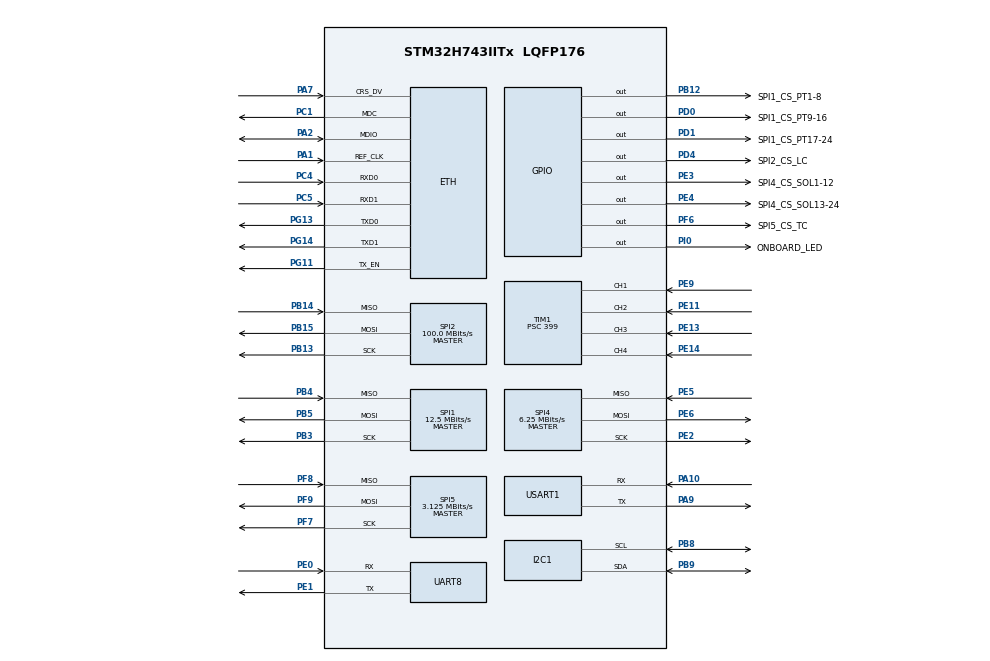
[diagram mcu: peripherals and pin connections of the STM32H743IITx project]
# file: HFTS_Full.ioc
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CORTEX_M7.default_mode_Activation=1
ETH.MediaInterface=HAL_ETH_RMII_MODE
FREERTOS.Tasks01=defaultTask,0,128,StartDefaultTask,Default,NULL,Dynamic,NULL,NULL
I2C1.Timing=0x10C0ECFF
Mcu.Family=STM32H7
Mcu.Name=STM32H743IITx
Mcu.Package=LQFP176
Mcu.UserConstants=I2C1_BUS_HZ,100000;TMP117_ADDRESS,0b1001000x
NVIC.PriorityGroup=NVIC_PRIORITYGROUP_4
NVIC.TIM1_CC_IRQn=true\:5\:0\:false\:false\:true\:true\:true\:true\:true
PA1.Mode=RMII
PA1.Signal=ETH_REF_CLK
PA10.Mode=Asynchronous
PA10.Signal=USART1_RX
PA13\ (JTMS/SWDIO).Mode=Serial_Wire
PA13\ (JTMS/SWDIO).Signal=DEBUG_JTMS-SWDIO
PA14\ (JTCK/SWCLK).Mode=Serial_Wire
PA14\ (JTCK/SWCLK).Signal=DEBUG_JTCK-SWCLK
PA2.Mode=RMII
PA2.Signal=ETH_MDIO
PA7.Mode=RMII
PA7.Signal=ETH_CRS_DV
PA9.Mode=Asynchronous
PA9.Signal=USART1_TX
PB12.GPIO_Label=SPI1_CS_PT1-8
PB12.PinState=GPIO_PIN_SET
PB12.Signal=GPIO_Output
PB13.Mode=Full_Duplex_Master
PB13.Signal=SPI2_SCK
PB14.Mode=Full_Duplex_Master
PB14.Signal=SPI2_MISO
PB15.Mode=Full_Duplex_Master
PB15.Signal=SPI2_MOSI
PB3\ (JTDO/TRACESWO).Mode=Full_Duplex_Master
PB3\ (JTDO/TRACESWO).Signal=SPI1_SCK
PB4\ (NJTRST).Mode=Full_Duplex_Master
PB4\ (NJTRST).Signal=SPI1_MISO
PB5.Mode=Full_Duplex_Master
PB5.Signal=SPI1_MOSI
PB8.Mode=I2C
PB8.Signal=I2C1_SCL
PB9.Mode=I2C
PB9.Signal=I2C1_SDA
PC1.Mode=RMII
PC1.Signal=ETH_MDC
PC4.Mode=RMII
PC4.Signal=ETH_RXD0
PC5.Mode=RMII
PC5.Signal=ETH_RXD1
PD0.GPIO_Label=SPI1_CS_PT9-16
PD0.PinState=GPIO_PIN_SET
PD0.Signal=GPIO_Output
PD1.GPIO_Label=SPI1_CS_PT17-24
PD1.PinState=GPIO_PIN_SET
PD1.Signal=GPIO_Output
PD4.GPIO_Label=SPI2_CS_LC
PD4.PinState=GPIO_PIN_SET
PD4.Signal=GPIO_Output
PE0.Mode=Asynchronous
PE0.Signal=UART8_RX
PE1.Mode=Asynchronous
PE1.Signal=UART8_TX
PE11.Signal=S_TIM1_CH2
PE13.Signal=S_TIM1_CH3
PE14.Signal=S_TIM1_CH4
PE2.Mode=Full_Duplex_Master
PE2.Signal=SPI4_SCK
PE3.GPIO_Label=SPI4_CS_SOL1-12
PE3.PinState=GPIO_PIN_SET
PE3.Signal=GPIO_Output
PE4.GPIO_Label=SPI4_CS_SOL13-24
PE4.PinState=GPIO_PIN_SET
PE4.Signal=GPIO_Output
PE5.Mode=Full_Duplex_Master
PE5.Signal=SPI4_MISO
PE6.Mode=Full_Duplex_Master
PE6.Signal=SPI4_MOSI
PE9.Signal=S_TIM1_CH1
PF6.GPIO_Label=SPI5_CS_TC
PF6.PinState=GPIO_PIN_SET
PF6.Signal=GPIO_Output
PF7.Mode=Full_Duplex_Master
PF7.Signal=SPI5_SCK
PF8.Mode=Full_Duplex_Master
PF8.Signal=SPI5_MISO
PF9.Mode=Full_Duplex_Master
PF9.Signal=SPI5_MOSI
PG11.Mode=RMII
PG11.Signal=ETH_TX_EN
PG13.Mode=RMII
PG13.Signal=ETH_TXD0
PG14.Mode=RMII
PG14.Signal=ETH_TXD1
PH0-OSC_IN\ (PH0).Mode=HSE-External-Oscillator
PH0-OSC_IN\ (PH0).Signal=RCC_OSC_IN
PH1-OSC_OUT\ (PH1).Mode=HSE-External-Oscillator
PH1-OSC_OUT\ (PH1).Signal=RCC_OSC_OUT
PI0.GPIO_Label=ONBOARD_LED
PI0.Signal=GPIO_Output
ProjectManager.HeapSize=0x200
ProjectManager.StackSize=0x400
ProjectManager.TargetToolchain=STM32CubeIDE
RCC.ADCFreq_Value=50000000
RCC.APB1Freq_Value=100000000
RCC.APB2Freq_Value=100000000
RCC.APB3Freq_Value=100000000
RCC.APB4Freq_Value=100000000
RCC.CortexFreq_Value=400000000
RCC.D1PPRE=RCC_APB3_DIV2
RCC.D2PPRE1=RCC_APB1_DIV2
RCC.D2PPRE2=RCC_APB2_DIV2
RCC.D3PPRE=RCC_APB4_DIV2
RCC.DIVM1=2
RCC.DIVM2=2
RCC.DIVN1=64
RCC.DIVN2=16
RCC.DIVP2=4
RCC.DIVQ1=4
RCC.DIVQ2=4
RCC.HCLKFreq_Value=200000000
RCC.HPRE=RCC_HCLK_DIV2
RCC.PLL2FRACN=0
RCC.PLL3FRACN=0
RCC.PLLFRACN=0
RCC.PLLSourceVirtual=RCC_PLLSOURCE_HSE
RCC.SYSCLKFreq_VALUE=400000000
RCC.SYSCLKSource=RCC_SYSCLKSOURCE_PLLCLK
RCC.Spi45ClockSelection=RCC_SPI45CLKSOURCE_PLL2
RCC.USBFreq_Value=200000000
SH.S_TIM1_CH1.0=TIM1_CH1,Input_Capture1_from_TI1
SH.S_TIM1_CH2.0=TIM1_CH2,Input_Capture2_from_TI2
SH.S_TIM1_CH3.0=TIM1_CH3,Input_Capture3_from_TI3
SH.S_TIM1_CH4.0=TIM1_CH4,Input_Capture4_from_TI4
SPI1.BaudRatePrescaler=SPI_BAUDRATEPRESCALER_16
SPI1.CalculateBaudRate=12.5 MBits/s
SPI1.Direction=SPI_DIRECTION_2LINES
SPI1.Mode=SPI_MODE_MASTER
SPI1.VirtualType=VM_MASTER
SPI2.CalculateBaudRate=100.0 MBits/s
SPI2.Direction=SPI_DIRECTION_2LINES
SPI2.Mode=SPI_MODE_MASTER
SPI2.VirtualType=VM_MASTER
SPI4.BaudRatePrescaler=SPI_BAUDRATEPRESCALER_8
SPI4.CalculateBaudRate=6.25 MBits/s
SPI4.Direction=SPI_DIRECTION_2LINES
SPI4.Mode=SPI_MODE_MASTER
SPI4.VirtualType=VM_MASTER
SPI5.BaudRatePrescaler=SPI_BAUDRATEPRESCALER_16
SPI5.CalculateBaudRate=3.125 MBits/s
SPI5.Direction=SPI_DIRECTION_2LINES
SPI5.Mode=SPI_MODE_MASTER
SPI5.VirtualType=VM_MASTER
TIM1.Channel-Input_Capture1_from_TI1=TIM_CHANNEL_1
TIM1.Channel-Input_Capture2_from_TI2=TIM_CHANNEL_2
TIM1.Channel-Input_Capture3_from_TI3=TIM_CHANNEL_3
TIM1.Channel-Input_Capture4_from_TI4=TIM_CHANNEL_4
TIM1.ICFilter_CH1=2
TIM1.Prescaler=399
USART1.VirtualMode-Asynchronous=VM_ASYNC
VP_FREERTOS_VS_CMSIS_V1.Mode=CMSIS_V1
VP_MEMORYMAP_VS_MEMORYMAP.Mode=CurAppReg
VP_TIM1_VS_ClockSourceINT.Mode=Internal
board=custom

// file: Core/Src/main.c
/* USER CODE BEGIN Header */
/**
  ******************************************************************************
  * @file           : main.c
  * @brief          : Main program body
  ******************************************************************************
  * @attention
  *
  * Copyright (c) 2026 STMicroelectronics.
  * All rights reserved.
  *
  * This software is licensed under terms that can be found in the LICENSE file
  * in the root directory of this software component.
  * If no LICENSE file comes with this software, it is provided AS-IS.
  *
  ******************************************************************************
  */
/* USER CODE END Header */
#include "main.h"
#include "string.h"
#include "cmsis_os.h"

#if defined ( __ICCARM__ ) /*!< IAR Compiler */
#pragma location=0x30000000
ETH_DMADescTypeDef  DMARxDscrTab[ETH_RX_DESC_CNT]; /* Ethernet Rx DMA Descriptors */
#pragma location=0x30000080
ETH_DMADescTypeDef  DMATxDscrTab[ETH_TX_DESC_CNT]; /* Ethernet Tx DMA Descriptors */

#elif defined ( __CC_ARM )  /* MDK ARM Compiler */

__attribute__((at(0x30000000))) ETH_DMADescTypeDef  DMARxDscrTab[ETH_RX_DESC_CNT]; /* Ethernet Rx DMA Descriptors */
__attribute__((at(0x30000080))) ETH_DMADescTypeDef  DMATxDscrTab[ETH_TX_DESC_CNT]; /* Ethernet Tx DMA Descriptors */

#elif defined ( __GNUC__ ) /* GNU Compiler */

ETH_DMADescTypeDef DMARxDscrTab[ETH_RX_DESC_CNT] __attribute__((section(".RxDescripSection"))); /* Ethernet Rx DMA Descriptors */
ETH_DMADescTypeDef DMATxDscrTab[ETH_TX_DESC_CNT] __attribute__((section(".TxDescripSection")));   /* Ethernet Tx DMA Descriptors */
#endif

ETH_TxPacketConfig TxConfig;

ETH_HandleTypeDef heth;

I2C_HandleTypeDef hi2c1;

SPI_HandleTypeDef hspi1;
SPI_HandleTypeDef hspi2;
SPI_HandleTypeDef hspi4;
SPI_HandleTypeDef hspi5;

TIM_HandleTypeDef htim1;

UART_HandleTypeDef huart8;
UART_HandleTypeDef huart1;

osThreadId defaultTaskHandle;

void SystemClock_Config(void);
void PeriphCommonClock_Config(void);
static void MPU_Config(void);
static void MX_GPIO_Init(void);
static void MX_ETH_Init(void);
static void MX_TIM1_Init(void);
static void MX_I2C1_Init(void);
static void MX_SPI1_Init(void);
static void MX_SPI2_Init(void);
static void MX_SPI4_Init(void);
static void MX_SPI5_Init(void);
static void MX_UART8_Init(void);
static void MX_USART1_UART_Init(void);
void StartDefaultTask(void const * argument);

int main(void)
{

  /* MPU Configuration--------------------------------------------------------*/
  MPU_Config();

  /* MCU Configuration--------------------------------------------------------*/

  /* Reset of all peripherals, Initializes the Flash interface and the Systick. */
  HAL_Init();

  /* Configure the system clock */
  SystemClock_Config();

  /* Configure the peripherals common clocks */
  PeriphCommonClock_Config();

  /* Initialize all configured peripherals */
  MX_GPIO_Init();

  MX_ETH_Init();
  MX_TIM1_Init();
  MX_I2C1_Init();
  MX_SPI1_Init();
  MX_SPI2_Init();
  MX_SPI4_Init();
  MX_SPI5_Init();
  MX_UART8_Init();
  MX_USART1_UART_Init();

  /* Create the thread(s) */
  /* definition and creation of defaultTask */
  osThreadDef(defaultTask, StartDefaultTask, osPriorityNormal, 0, 128);
  defaultTaskHandle = osThreadCreate(osThread(defaultTask), NULL);

  /* Start scheduler */
  osKernelStart();

  /* We should never get here as control is now taken by the scheduler */

  /* Infinite loop */
  while (1)
  {

  }
}

void SystemClock_Config(void)
{
  RCC_OscInitTypeDef RCC_OscInitStruct = {0};
  RCC_ClkInitTypeDef RCC_ClkInitStruct = {0};

  /** Supply configuration update enable
  */
  HAL_PWREx_ConfigSupply(PWR_LDO_SUPPLY);

  /** Configure the main internal regulator output voltage
  */
  __HAL_PWR_VOLTAGESCALING_CONFIG(PWR_REGULATOR_VOLTAGE_SCALE1);

  while(!__HAL_PWR_GET_FLAG(PWR_FLAG_VOSRDY)) {}

  /** Initializes the RCC Oscillators according to the specified parameters
  * in the RCC_OscInitTypeDef structure.
  */
  RCC_OscInitStruct.OscillatorType = RCC_OSCILLATORTYPE_HSE;
  RCC_OscInitStruct.HSEState = RCC_HSE_ON;
  RCC_OscInitStruct.PLL.PLLState = RCC_PLL_ON;
  RCC_OscInitStruct.PLL.PLLSource = RCC_PLLSOURCE_HSE;
  RCC_OscInitStruct.PLL.PLLM = 2;
  RCC_OscInitStruct.PLL.PLLN = 64;
  RCC_OscInitStruct.PLL.PLLP = 2;
  RCC_OscInitStruct.PLL.PLLQ = 4;
  RCC_OscInitStruct.PLL.PLLR = 2;
  RCC_OscInitStruct.PLL.PLLRGE = RCC_PLL1VCIRANGE_3;
  RCC_OscInitStruct.PLL.PLLVCOSEL = RCC_PLL1VCOWIDE;
  RCC_OscInitStruct.PLL.PLLFRACN = 0;
  if (HAL_RCC_OscConfig(&RCC_OscInitStruct) != HAL_OK)
  {
    Error_Handler();
  }

  /** Initializes the CPU, AHB and APB buses clocks
  */
  RCC_ClkInitStruct.ClockType = RCC_CLOCKTYPE_HCLK|RCC_CLOCKTYPE_SYSCLK
                              |RCC_CLOCKTYPE_PCLK1|RCC_CLOCKTYPE_PCLK2
                              |RCC_CLOCKTYPE_D3PCLK1|RCC_CLOCKTYPE_D1PCLK1;
  RCC_ClkInitStruct.SYSCLKSource = RCC_SYSCLKSOURCE_PLLCLK;
  RCC_ClkInitStruct.SYSCLKDivider = RCC_SYSCLK_DIV1;
  RCC_ClkInitStruct.AHBCLKDivider = RCC_HCLK_DIV2;
  RCC_ClkInitStruct.APB3CLKDivider = RCC_APB3_DIV2;
  RCC_ClkInitStruct.APB1CLKDivider = RCC_APB1_DIV2;
  RCC_ClkInitStruct.APB2CLKDivider = RCC_APB2_DIV2;
  RCC_ClkInitStruct.APB4CLKDivider = RCC_APB4_DIV2;

  if (HAL_RCC_ClockConfig(&RCC_ClkInitStruct, FLASH_LATENCY_2) != HAL_OK)
  {
    Error_Handler();
  }
}

void PeriphCommonClock_Config(void)
{
  RCC_PeriphCLKInitTypeDef PeriphClkInitStruct = {0};

  /** Initializes the peripherals clock
  */
  PeriphClkInitStruct.PeriphClockSelection = RCC_PERIPHCLK_SPI4|RCC_PERIPHCLK_SPI5;
  PeriphClkInitStruct.PLL2.PLL2M = 2;
  PeriphClkInitStruct.PLL2.PLL2N = 16;
  PeriphClkInitStruct.PLL2.PLL2P = 4;
  PeriphClkInitStruct.PLL2.PLL2Q = 4;
  PeriphClkInitStruct.PLL2.PLL2R = 2;
  PeriphClkInitStruct.PLL2.PLL2RGE = RCC_PLL2VCIRANGE_3;
  PeriphClkInitStruct.PLL2.PLL2VCOSEL = RCC_PLL2VCOWIDE;
  PeriphClkInitStruct.PLL2.PLL2FRACN = 0;
  PeriphClkInitStruct.Spi45ClockSelection = RCC_SPI45CLKSOURCE_PLL2;
  if (HAL_RCCEx_PeriphCLKConfig(&PeriphClkInitStruct) != HAL_OK)
  {
    Error_Handler();
  }
}

static void MX_ETH_Init(void)
{

   static uint8_t MACAddr[6];

  heth.Instance = ETH;
  MACAddr[0] = 0x00;
  MACAddr[1] = 0x80;
  MACAddr[2] = 0xE1;
  MACAddr[3] = 0x00;
  MACAddr[4] = 0x00;
  MACAddr[5] = 0x00;
  heth.Init.MACAddr = &MACAddr[0];
  heth.Init.MediaInterface = HAL_ETH_RMII_MODE;
  heth.Init.TxDesc = DMATxDscrTab;
  heth.Init.RxDesc = DMARxDscrTab;
  heth.Init.RxBuffLen = 1536;

  if (HAL_ETH_Init(&heth) != HAL_OK)
  {
    Error_Handler();
  }

  memset(&TxConfig, 0 , sizeof(ETH_TxPacketConfig));
  TxConfig.Attributes = ETH_TX_PACKETS_FEATURES_CSUM | ETH_TX_PACKETS_FEATURES_CRCPAD;
  TxConfig.ChecksumCtrl = ETH_CHECKSUM_IPHDR_PAYLOAD_INSERT_PHDR_CALC;
  TxConfig.CRCPadCtrl = ETH_CRC_PAD_INSERT;

}

static void MX_I2C1_Init(void)
{

  hi2c1.Instance = I2C1;
  hi2c1.Init.Timing = 0x10C0ECFF;
  hi2c1.Init.OwnAddress1 = 0;
  hi2c1.Init.AddressingMode = I2C_ADDRESSINGMODE_7BIT;
  hi2c1.Init.DualAddressMode = I2C_DUALADDRESS_DISABLE;
  hi2c1.Init.OwnAddress2 = 0;
  hi2c1.Init.OwnAddress2Masks = I2C_OA2_NOMASK;
  hi2c1.Init.GeneralCallMode = I2C_GENERALCALL_DISABLE;
  hi2c1.Init.NoStretchMode = I2C_NOSTRETCH_DISABLE;
  if (HAL_I2C_Init(&hi2c1) != HAL_OK)
  {
    Error_Handler();
  }

  /** Configure Analogue filter
  */
  if (HAL_I2CEx_ConfigAnalogFilter(&hi2c1, I2C_ANALOGFILTER_ENABLE) != HAL_OK)
  {
    Error_Handler();
  }

  /** Configure Digital filter
  */
  if (HAL_I2CEx_ConfigDigitalFilter(&hi2c1, 0) != HAL_OK)
  {
    Error_Handler();
  }

}

static void MX_SPI1_Init(void)
{

  /* SPI1 parameter configuration*/
  hspi1.Instance = SPI1;
  hspi1.Init.Mode = SPI_MODE_MASTER;
  hspi1.Init.Direction = SPI_DIRECTION_2LINES;
  hspi1.Init.DataSize = SPI_DATASIZE_4BIT;
  hspi1.Init.CLKPolarity = SPI_POLARITY_LOW;
  hspi1.Init.CLKPhase = SPI_PHASE_1EDGE;
  hspi1.Init.NSS = SPI_NSS_SOFT;
  hspi1.Init.BaudRatePrescaler = SPI_BAUDRATEPRESCALER_16;
  hspi1.Init.FirstBit = SPI_FIRSTBIT_MSB;
  hspi1.Init.TIMode = SPI_TIMODE_DISABLE;
  hspi1.Init.CRCCalculation = SPI_CRCCALCULATION_DISABLE;
  hspi1.Init.CRCPolynomial = 0x0;
  hspi1.Init.NSSPMode = SPI_NSS_PULSE_ENABLE;
  hspi1.Init.NSSPolarity = SPI_NSS_POLARITY_LOW;
  hspi1.Init.FifoThreshold = SPI_FIFO_THRESHOLD_01DATA;
  hspi1.Init.TxCRCInitializationPattern = SPI_CRC_INITIALIZATION_ALL_ZERO_PATTERN;
  hspi1.Init.RxCRCInitializationPattern = SPI_CRC_INITIALIZATION_ALL_ZERO_PATTERN;
  hspi1.Init.MasterSSIdleness = SPI_MASTER_SS_IDLENESS_00CYCLE;
  hspi1.Init.MasterInterDataIdleness = SPI_MASTER_INTERDATA_IDLENESS_00CYCLE;
  hspi1.Init.MasterReceiverAutoSusp = SPI_MASTER_RX_AUTOSUSP_DISABLE;
  hspi1.Init.MasterKeepIOState = SPI_MASTER_KEEP_IO_STATE_DISABLE;
  hspi1.Init.IOSwap = SPI_IO_SWAP_DISABLE;
  if (HAL_SPI_Init(&hspi1) != HAL_OK)
  {
    Error_Handler();
  }

}

static void MX_SPI2_Init(void)
{

  /* SPI2 parameter configuration*/
  hspi2.Instance = SPI2;
  hspi2.Init.Mode = SPI_MODE_MASTER;
  hspi2.Init.Direction = SPI_DIRECTION_2LINES;
  hspi2.Init.DataSize = SPI_DATASIZE_4BIT;
  hspi2.Init.CLKPolarity = SPI_POLARITY_LOW;
  hspi2.Init.CLKPhase = SPI_PHASE_1EDGE;
  hspi2.Init.NSS = SPI_NSS_SOFT;
  hspi2.Init.BaudRatePrescaler = SPI_BAUDRATEPRESCALER_2;
  hspi2.Init.FirstBit = SPI_FIRSTBIT_MSB;
  hspi2.Init.TIMode = SPI_TIMODE_DISABLE;
  hspi2.Init.CRCCalculation = SPI_CRCCALCULATION_DISABLE;
  hspi2.Init.CRCPolynomial = 0x0;
  hspi2.Init.NSSPMode = SPI_NSS_PULSE_ENABLE;
  hspi2.Init.NSSPolarity = SPI_NSS_POLARITY_LOW;
  hspi2.Init.FifoThreshold = SPI_FIFO_THRESHOLD_01DATA;
  hspi2.Init.TxCRCInitializationPattern = SPI_CRC_INITIALIZATION_ALL_ZERO_PATTERN;
  hspi2.Init.RxCRCInitializationPattern = SPI_CRC_INITIALIZATION_ALL_ZERO_PATTERN;
  hspi2.Init.MasterSSIdleness = SPI_MASTER_SS_IDLENESS_00CYCLE;
  hspi2.Init.MasterInterDataIdleness = SPI_MASTER_INTERDATA_IDLENESS_00CYCLE;
  hspi2.Init.MasterReceiverAutoSusp = SPI_MASTER_RX_AUTOSUSP_DISABLE;
  hspi2.Init.MasterKeepIOState = SPI_MASTER_KEEP_IO_STATE_DISABLE;
  hspi2.Init.IOSwap = SPI_IO_SWAP_DISABLE;
  if (HAL_SPI_Init(&hspi2) != HAL_OK)
  {
    Error_Handler();
  }

}

static void MX_SPI4_Init(void)
{

  /* SPI4 parameter configuration*/
  hspi4.Instance = SPI4;
  hspi4.Init.Mode = SPI_MODE_MASTER;
  hspi4.Init.Direction = SPI_DIRECTION_2LINES;
  hspi4.Init.DataSize = SPI_DATASIZE_4BIT;
  hspi4.Init.CLKPolarity = SPI_POLARITY_LOW;
  hspi4.Init.CLKPhase = SPI_PHASE_1EDGE;
  hspi4.Init.NSS = SPI_NSS_SOFT;
  hspi4.Init.BaudRatePrescaler = SPI_BAUDRATEPRESCALER_8;
  hspi4.Init.FirstBit = SPI_FIRSTBIT_MSB;
  hspi4.Init.TIMode = SPI_TIMODE_DISABLE;
  hspi4.Init.CRCCalculation = SPI_CRCCALCULATION_DISABLE;
  hspi4.Init.CRCPolynomial = 0x0;
  hspi4.Init.NSSPMode = SPI_NSS_PULSE_ENABLE;
  hspi4.Init.NSSPolarity = SPI_NSS_POLARITY_LOW;
  hspi4.Init.FifoThreshold = SPI_FIFO_THRESHOLD_01DATA;
  hspi4.Init.TxCRCInitializationPattern = SPI_CRC_INITIALIZATION_ALL_ZERO_PATTERN;
  hspi4.Init.RxCRCInitializationPattern = SPI_CRC_INITIALIZATION_ALL_ZERO_PATTERN;
  hspi4.Init.MasterSSIdleness = SPI_MASTER_SS_IDLENESS_00CYCLE;
  hspi4.Init.MasterInterDataIdleness = SPI_MASTER_INTERDATA_IDLENESS_00CYCLE;
  hspi4.Init.MasterReceiverAutoSusp = SPI_MASTER_RX_AUTOSUSP_DISABLE;
  hspi4.Init.MasterKeepIOState = SPI_MASTER_KEEP_IO_STATE_DISABLE;
  hspi4.Init.IOSwap = SPI_IO_SWAP_DISABLE;
  if (HAL_SPI_Init(&hspi4) != HAL_OK)
  {
    Error_Handler();
  }

}

static void MX_SPI5_Init(void)
{

  /* SPI5 parameter configuration*/
  hspi5.Instance = SPI5;
  hspi5.Init.Mode = SPI_MODE_MASTER;
  hspi5.Init.Direction = SPI_DIRECTION_2LINES;
  hspi5.Init.DataSize = SPI_DATASIZE_4BIT;
  hspi5.Init.CLKPolarity = SPI_POLARITY_LOW;
  hspi5.Init.CLKPhase = SPI_PHASE_1EDGE;
  hspi5.Init.NSS = SPI_NSS_SOFT;
  hspi5.Init.BaudRatePrescaler = SPI_BAUDRATEPRESCALER_16;
  hspi5.Init.FirstBit = SPI_FIRSTBIT_MSB;
  hspi5.Init.TIMode = SPI_TIMODE_DISABLE;
  hspi5.Init.CRCCalculation = SPI_CRCCALCULATION_DISABLE;
  hspi5.Init.CRCPolynomial = 0x0;
  hspi5.Init.NSSPMode = SPI_NSS_PULSE_ENABLE;
  hspi5.Init.NSSPolarity = SPI_NSS_POLARITY_LOW;
  hspi5.Init.FifoThreshold = SPI_FIFO_THRESHOLD_01DATA;
  hspi5.Init.TxCRCInitializationPattern = SPI_CRC_INITIALIZATION_ALL_ZERO_PATTERN;
  hspi5.Init.RxCRCInitializationPattern = SPI_CRC_INITIALIZATION_ALL_ZERO_PATTERN;
  hspi5.Init.MasterSSIdleness = SPI_MASTER_SS_IDLENESS_00CYCLE;
  hspi5.Init.MasterInterDataIdleness = SPI_MASTER_INTERDATA_IDLENESS_00CYCLE;
  hspi5.Init.MasterReceiverAutoSusp = SPI_MASTER_RX_AUTOSUSP_DISABLE;
  hspi5.Init.MasterKeepIOState = SPI_MASTER_KEEP_IO_STATE_DISABLE;
  hspi5.Init.IOSwap = SPI_IO_SWAP_DISABLE;
  if (HAL_SPI_Init(&hspi5) != HAL_OK)
  {
    Error_Handler();
  }

}

static void MX_TIM1_Init(void)
{

  TIM_ClockConfigTypeDef sClockSourceConfig = {0};
  TIM_MasterConfigTypeDef sMasterConfig = {0};
  TIM_IC_InitTypeDef sConfigIC = {0};

  htim1.Instance = TIM1;
  htim1.Init.Prescaler = 399;
  htim1.Init.CounterMode = TIM_COUNTERMODE_UP;
  htim1.Init.Period = 65535;
  htim1.Init.ClockDivision = TIM_CLOCKDIVISION_DIV1;
  htim1.Init.RepetitionCounter = 0;
  htim1.Init.AutoReloadPreload = TIM_AUTORELOAD_PRELOAD_DISABLE;
  if (HAL_TIM_Base_Init(&htim1) != HAL_OK)
  {
    Error_Handler();
  }
  sClockSourceConfig.ClockSource = TIM_CLOCKSOURCE_INTERNAL;
  if (HAL_TIM_ConfigClockSource(&htim1, &sClockSourceConfig) != HAL_OK)
  {
    Error_Handler();
  }
  if (HAL_TIM_IC_Init(&htim1) != HAL_OK)
  {
    Error_Handler();
  }
  sMasterConfig.MasterOutputTrigger = TIM_TRGO_RESET;
  sMasterConfig.MasterOutputTrigger2 = TIM_TRGO2_RESET;
  sMasterConfig.MasterSlaveMode = TIM_MASTERSLAVEMODE_DISABLE;
  if (HAL_TIMEx_MasterConfigSynchronization(&htim1, &sMasterConfig) != HAL_OK)
  {
    Error_Handler();
  }
  sConfigIC.ICPolarity = TIM_INPUTCHANNELPOLARITY_RISING;
  sConfigIC.ICSelection = TIM_ICSELECTION_DIRECTTI;
  sConfigIC.ICPrescaler = TIM_ICPSC_DIV1;
  sConfigIC.ICFilter = 2;
  if (HAL_TIM_IC_ConfigChannel(&htim1, &sConfigIC, TIM_CHANNEL_1) != HAL_OK)
  {
    Error_Handler();
  }
  sConfigIC.ICFilter = 0;
  if (HAL_TIM_IC_ConfigChannel(&htim1, &sConfigIC, TIM_CHANNEL_2) != HAL_OK)
  {
    Error_Handler();
  }
  if (HAL_TIM_IC_ConfigChannel(&htim1, &sConfigIC, TIM_CHANNEL_3) != HAL_OK)
  {
    Error_Handler();
  }
  if (HAL_TIM_IC_ConfigChannel(&htim1, &sConfigIC, TIM_CHANNEL_4) != HAL_OK)
  {
    Error_Handler();
  }

}

static void MX_UART8_Init(void)
{

  huart8.Instance = UART8;
  huart8.Init.BaudRate = 115200;
  huart8.Init.WordLength = UART_WORDLENGTH_8B;
  huart8.Init.StopBits = UART_STOPBITS_1;
  huart8.Init.Parity = UART_PARITY_NONE;
  huart8.Init.Mode = UART_MODE_TX_RX;
  huart8.Init.HwFlowCtl = UART_HWCONTROL_NONE;
  huart8.Init.OverSampling = UART_OVERSAMPLING_16;
  huart8.Init.OneBitSampling = UART_ONE_BIT_SAMPLE_DISABLE;
  huart8.Init.ClockPrescaler = UART_PRESCALER_DIV1;
  huart8.AdvancedInit.AdvFeatureInit = UART_ADVFEATURE_NO_INIT;
  if (HAL_UART_Init(&huart8) != HAL_OK)
  {
    Error_Handler();
  }
  if (HAL_UARTEx_SetTxFifoThreshold(&huart8, UART_TXFIFO_THRESHOLD_1_8) != HAL_OK)
  {
    Error_Handler();
  }
  if (HAL_UARTEx_SetRxFifoThreshold(&huart8, UART_RXFIFO_THRESHOLD_1_8) != HAL_OK)
  {
    Error_Handler();
  }
  if (HAL_UARTEx_DisableFifoMode(&huart8) != HAL_OK)
  {
    Error_Handler();
  }

}

static void MX_USART1_UART_Init(void)
{

  huart1.Instance = USART1;
  huart1.Init.BaudRate = 115200;
  huart1.Init.WordLength = UART_WORDLENGTH_8B;
  huart1.Init.StopBits = UART_STOPBITS_1;
  huart1.Init.Parity = UART_PARITY_NONE;
  huart1.Init.Mode = UART_MODE_TX_RX;
  huart1.Init.HwFlowCtl = UART_HWCONTROL_NONE;
  huart1.Init.OverSampling = UART_OVERSAMPLING_16;
  huart1.Init.OneBitSampling = UART_ONE_BIT_SAMPLE_DISABLE;
  huart1.Init.ClockPrescaler = UART_PRESCALER_DIV1;
  huart1.AdvancedInit.AdvFeatureInit = UART_ADVFEATURE_NO_INIT;
  if (HAL_UART_Init(&huart1) != HAL_OK)
  {
    Error_Handler();
  }
  if (HAL_UARTEx_SetTxFifoThreshold(&huart1, UART_TXFIFO_THRESHOLD_1_8) != HAL_OK)
  {
    Error_Handler();
  }
  if (HAL_UARTEx_SetRxFifoThreshold(&huart1, UART_RXFIFO_THRESHOLD_1_8) != HAL_OK)
  {
    Error_Handler();
  }
  if (HAL_UARTEx_DisableFifoMode(&huart1) != HAL_OK)
  {
    Error_Handler();
  }

}

static void MX_GPIO_Init(void)
{
  GPIO_InitTypeDef GPIO_InitStruct = {0};

  /* GPIO Ports Clock Enable */
  __HAL_RCC_GPIOE_CLK_ENABLE();
  __HAL_RCC_GPIOF_CLK_ENABLE();
  __HAL_RCC_GPIOH_CLK_ENABLE();
  __HAL_RCC_GPIOC_CLK_ENABLE();
  __HAL_RCC_GPIOA_CLK_ENABLE();
  __HAL_RCC_GPIOB_CLK_ENABLE();
  __HAL_RCC_GPIOI_CLK_ENABLE();
  __HAL_RCC_GPIOD_CLK_ENABLE();
  __HAL_RCC_GPIOG_CLK_ENABLE();

  /*Configure GPIO pin Output Level */
  HAL_GPIO_WritePin(GPIOE, SPI4_CS_SOL1_12_Pin|SPI4_CS_SOL13_24_Pin, GPIO_PIN_SET);

  /*Configure GPIO pin Output Level */
  HAL_GPIO_WritePin(SPI5_CS_TC_GPIO_Port, SPI5_CS_TC_Pin, GPIO_PIN_SET);

  /*Configure GPIO pin Output Level */
  HAL_GPIO_WritePin(SPI1_CS_PT1_8_GPIO_Port, SPI1_CS_PT1_8_Pin, GPIO_PIN_SET);

  /*Configure GPIO pin Output Level */
  HAL_GPIO_WritePin(ONBOARD_LED_GPIO_Port, ONBOARD_LED_Pin, GPIO_PIN_RESET);

  /*Configure GPIO pin Output Level */
  HAL_GPIO_WritePin(GPIOD, SPI1_CS_PT9_16_Pin|SPI1_CS_PT17_24_Pin|SPI2_CS_LC_Pin, GPIO_PIN_SET);

  /*Configure GPIO pins : SPI4_CS_SOL1_12_Pin SPI4_CS_SOL13_24_Pin */
  GPIO_InitStruct.Pin = SPI4_CS_SOL1_12_Pin|SPI4_CS_SOL13_24_Pin;
  GPIO_InitStruct.Mode = GPIO_MODE_OUTPUT_PP;
  GPIO_InitStruct.Pull = GPIO_NOPULL;
  GPIO_InitStruct.Speed = GPIO_SPEED_FREQ_LOW;
  HAL_GPIO_Init(GPIOE, &GPIO_InitStruct);

  /*Configure GPIO pin : SPI5_CS_TC_Pin */
  GPIO_InitStruct.Pin = SPI5_CS_TC_Pin;
  GPIO_InitStruct.Mode = GPIO_MODE_OUTPUT_PP;
  GPIO_InitStruct.Pull = GPIO_NOPULL;
  GPIO_InitStruct.Speed = GPIO_SPEED_FREQ_LOW;
  HAL_GPIO_Init(SPI5_CS_TC_GPIO_Port, &GPIO_InitStruct);

  /*Configure GPIO pin : SPI1_CS_PT1_8_Pin */
  GPIO_InitStruct.Pin = SPI1_CS_PT1_8_Pin;
  GPIO_InitStruct.Mode = GPIO_MODE_OUTPUT_PP;
  GPIO_InitStruct.Pull = GPIO_NOPULL;
  GPIO_InitStruct.Speed = GPIO_SPEED_FREQ_LOW;
  HAL_GPIO_Init(SPI1_CS_PT1_8_GPIO_Port, &GPIO_InitStruct);

  /*Configure GPIO pin : ONBOARD_LED_Pin */
  GPIO_InitStruct.Pin = ONBOARD_LED_Pin;
  GPIO_InitStruct.Mode = GPIO_MODE_OUTPUT_PP;
  GPIO_InitStruct.Pull = GPIO_NOPULL;
  GPIO_InitStruct.Speed = GPIO_SPEED_FREQ_LOW;
  HAL_GPIO_Init(ONBOARD_LED_GPIO_Port, &GPIO_InitStruct);

  /*Configure GPIO pins : SPI1_CS_PT9_16_Pin SPI1_CS_PT17_24_Pin SPI2_CS_LC_Pin */
  GPIO_InitStruct.Pin = SPI1_CS_PT9_16_Pin|SPI1_CS_PT17_24_Pin|SPI2_CS_LC_Pin;
  GPIO_InitStruct.Mode = GPIO_MODE_OUTPUT_PP;
  GPIO_InitStruct.Pull = GPIO_NOPULL;
  GPIO_InitStruct.Speed = GPIO_SPEED_FREQ_LOW;
  HAL_GPIO_Init(GPIOD, &GPIO_InitStruct);

}

void StartDefaultTask(void const * argument)
{
  /* USER CODE BEGIN 5 */
  static volatile uint32_t s_default_task_heartbeat = 0;
  /* Infinite loop */
  for(;;)
  {
    s_default_task_heartbeat++;
    HAL_GPIO_TogglePin(ONBOARD_LED_GPIO_Port, ONBOARD_LED_Pin);
    osDelay(500);
  }
  /* USER CODE END 5 */
}

 /* MPU Configuration */

void MPU_Config(void)
{
  MPU_Region_InitTypeDef MPU_InitStruct = {0};

  /* Disables the MPU */
  HAL_MPU_Disable();

  /** Initializes and configures the Region and the memory to be protected
  */
  MPU_InitStruct.Enable = MPU_REGION_ENABLE;
  MPU_InitStruct.Number = MPU_REGION_NUMBER0;
  MPU_InitStruct.BaseAddress = 0x0;
  MPU_InitStruct.Size = MPU_REGION_SIZE_4GB;
  MPU_InitStruct.SubRegionDisable = 0x87;
  MPU_InitStruct.TypeExtField = MPU_TEX_LEVEL0;
  MPU_InitStruct.AccessPermission = MPU_REGION_NO_ACCESS;
  MPU_InitStruct.DisableExec = MPU_INSTRUCTION_ACCESS_DISABLE;
  MPU_InitStruct.IsShareable = MPU_ACCESS_SHAREABLE;
  MPU_InitStruct.IsCacheable = MPU_ACCESS_NOT_CACHEABLE;
  MPU_InitStruct.IsBufferable = MPU_ACCESS_NOT_BUFFERABLE;

  HAL_MPU_ConfigRegion(&MPU_InitStruct);
  /* Enables the MPU */
  HAL_MPU_Enable(MPU_PRIVILEGED_DEFAULT);

}

void Error_Handler(void)
{
  __disable_irq();
  while (1)
  {
  }
}
